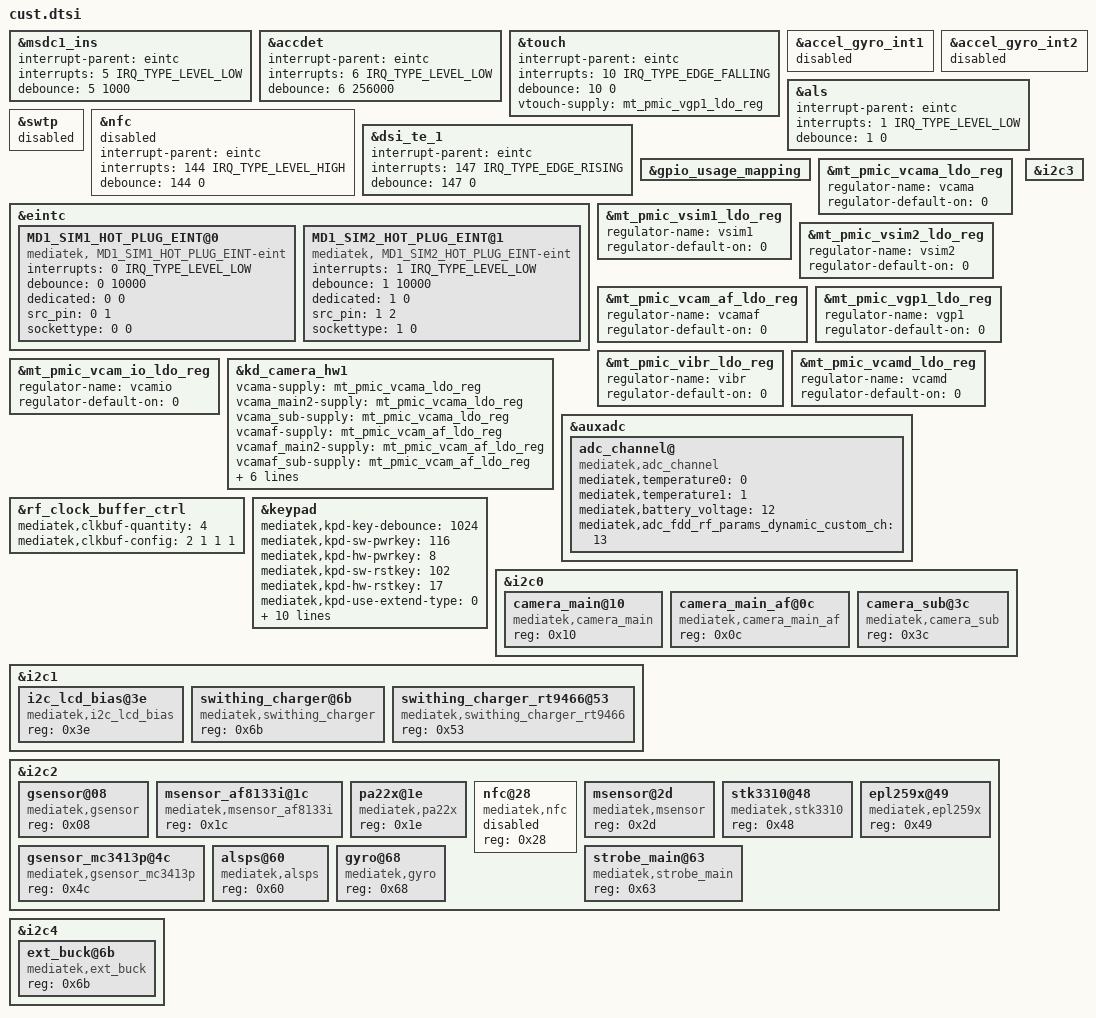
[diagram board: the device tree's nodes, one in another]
/*
 * Generated by MTK SP Drv_CodeGen Version 03.13.6  for MT6753. Copyright MediaTek Inc. (C) 2013.
 * Sun May 17 08:48:27 2026
 * Do Not Modify the File.
 */

#include <dt-bindings/interrupt-controller/irq.h>
#include <dt-bindings/interrupt-controller/arm-gic.h>

/*************************
 * EINT DTSI File
*************************/

&msdc1_ins {
	interrupt-parent = <&eintc>;
	interrupts = <5 IRQ_TYPE_LEVEL_LOW>;
	debounce = <5 1000>;
	status = "okay";
};
/* M1612 live DT dump: accdet EINT6 (m2note: EINT9). */
&accdet {
	interrupt-parent = <&eintc>;
	interrupts = <6 IRQ_TYPE_LEVEL_LOW>;
	debounce = <6 256000>;
	status = "okay";
};
&touch {
	interrupt-parent = <&eintc>;
	interrupts = <10 IRQ_TYPE_EDGE_FALLING>;
	debounce = <10 0>;
	status = "okay";
};
/* M1612 live DT dump: no accel_gyro_int nodes exist in stock (accel is
 * polled MC3XXX; EINT11/12 are cam1 rst/pnd GPIOs on this board). */
&accel_gyro_int1 {
	status = "disabled";
};
&accel_gyro_int2 {
	status = "disabled";
};
/* M1612 live DT dump: ALS/PS EINT1 (m2note: EINT18). */
&als {
	interrupt-parent = <&eintc>;
	interrupts = <1 IRQ_TYPE_LEVEL_LOW>;
	debounce = <1 0>;
	status = "okay";
};
/* M1612 live DT dump: no swtp node in stock DT. */
&swtp {
	status = "disabled";
};
&nfc {
	interrupt-parent = <&eintc>;
	interrupts = <144 IRQ_TYPE_LEVEL_HIGH>;
	debounce = <144 0>;
	status = "disabled";
};
&dsi_te_1 {
	interrupt-parent = <&eintc>;
	interrupts = <147 IRQ_TYPE_EDGE_RISING>;
	debounce = <147 0>;
	status = "okay";
};


/********************
 * GPIO USAGE MAPPING DTSI File
****************/

&gpio_usage_mapping {
};


&eintc {
	/* M1612 live DT dump: debounce 10000 (m2note 50000), sockettype 0. */
	MD1_SIM1_HOT_PLUG_EINT@0 {
		compatible = "mediatek, MD1_SIM1_HOT_PLUG_EINT-eint";
		interrupts = <0 IRQ_TYPE_LEVEL_LOW>;
		debounce = <0 10000>;
		dedicated = <0 0>;
		src_pin = <0 1>;
		sockettype = <0 0>;
	};

	MD1_SIM2_HOT_PLUG_EINT@1 {
		compatible = "mediatek, MD1_SIM2_HOT_PLUG_EINT-eint";
		interrupts = <1 IRQ_TYPE_LEVEL_LOW>;
		debounce = <1 10000>;
		dedicated = <1 0>;
		src_pin = <1 2>;
		sockettype = <1 0>;
	};
};


/*************************
 * PMIC DTSI File
*************************/

&mt_pmic_vcama_ldo_reg {
	regulator-name = "vcama";
	regulator-default-on = <0>; /* 0:skip, 1: off, 2:on */
	status = "okay";
};
&mt_pmic_vsim1_ldo_reg {
	regulator-name = "vsim1";
	regulator-default-on = <0>; /* 0:skip, 1: off, 2:on */
	status = "okay";
};
&mt_pmic_vsim2_ldo_reg {
	regulator-name = "vsim2";
	regulator-default-on = <0>; /* 0:skip, 1: off, 2:on */
	status = "okay";
};
&mt_pmic_vcam_af_ldo_reg {
	regulator-name = "vcamaf";
	regulator-default-on = <0>; /* 0:skip, 1: off, 2:on */
	status = "okay";
};
&mt_pmic_vgp1_ldo_reg {
	regulator-name = "vgp1";
	regulator-default-on = <0>; /* 0:skip, 1: off, 2:on */
	status = "okay";
};
&mt_pmic_vibr_ldo_reg {
	regulator-name = "vibr";
	regulator-default-on = <0>; /* 0:skip, 1: off, 2:on */
	status = "okay";
};
&mt_pmic_vcamd_ldo_reg {
	regulator-name = "vcamd";
	regulator-default-on = <0>; /* 0:skip, 1: off, 2:on */
	status = "okay";
};
&mt_pmic_vcam_io_ldo_reg {
	regulator-name = "vcamio";
	regulator-default-on = <0>; /* 0:skip, 1: off, 2:on */
	status = "okay";
};

&kd_camera_hw1 {
	vcama-supply = <&mt_pmic_vcama_ldo_reg>;
	vcama_main2-supply = <&mt_pmic_vcama_ldo_reg>;
	vcama_sub-supply = <&mt_pmic_vcama_ldo_reg>;

	vcamaf-supply = <&mt_pmic_vcam_af_ldo_reg>;
	vcamaf_main2-supply = <&mt_pmic_vcam_af_ldo_reg>;
	vcamaf_sub-supply = <&mt_pmic_vcam_af_ldo_reg>;

	vcamd-supply = <&mt_pmic_vcamd_ldo_reg>;
	vcamd_main2-supply = <&mt_pmic_vcamd_ldo_reg>;
	vcamd_sub-supply = <&mt_pmic_vcamd_ldo_reg>;

	vcamio-supply = <&mt_pmic_vcam_io_ldo_reg>;
	vcamio_main2-supply = <&mt_pmic_vcam_io_ldo_reg>;
	vcamio_sub-supply = <&mt_pmic_vcam_io_ldo_reg>;

	status = "okay";
};

&touch {
	vtouch-supply = <&mt_pmic_vgp1_ldo_reg>;
	status = "okay";
};


/********************************************
 *ADC DTSI File
********************************************/

&auxadc {
	adc_channel@ {
		compatible = "mediatek,adc_channel";
		mediatek,temperature0 = <0>;
		mediatek,temperature1 = <1>;
		/* M1612 live DT (soc/adc_hw@11001000/adc_channel@): battery_voltage
		 * ch 12, adc_fdd_rf_params_dynamic_custom_ch 13. */
		mediatek,battery_voltage = <12>;
		mediatek,adc_fdd_rf_params_dynamic_custom_ch = <13>;
		status = "okay";
	};
};


/**********************************************
 *CLK_BUF DTSI File
********************************************/

&rf_clock_buffer_ctrl {
	mediatek,clkbuf-quantity = <4>;
	mediatek,clkbuf-config = <2 1 1 1>;
	status = "okay";
};


/**********************************************
 *Keypad DTSI File
********************************************/

&keypad{
	mediatek,kpd-key-debounce = <1024>;
	mediatek,kpd-sw-pwrkey = <116>;
	mediatek,kpd-hw-pwrkey = <8>;
	mediatek,kpd-sw-rstkey = <102>;
	mediatek,kpd-hw-rstkey = <17>;
	mediatek,kpd-use-extend-type = <0>;
	/*HW Keycode [0~71] -> Linux Keycode*/
	mediatek,kpd-hw-map-num = <72>;
	mediatek,kpd-hw-init-map = <114 115 0 0 0 0 0 0 0 0 0 0 0 0 0 0 0 0 0 0 0 0 0 0
				0 0 0 0 0 0 0 0 0 0 0 0 0 0 0 0 0 0 0 0 0 0 0 0 
				0 0 0 0 0 0 0 0 0 0 0 0 0 0 0 0 0 0 0 0 0 0 0 0 >;
	mediatek,kpd-pwrkey-eint-gpio = <0>;
	mediatek,kpd-pwkey-gpio-din  = <0>;
	/* M1612 live DT dump: dl-key0=1 dl-key1=0 dl-key2=8. */
	mediatek,kpd-hw-dl-key0 = <1>;
	mediatek,kpd-hw-dl-key1 = <0>;
	mediatek,kpd-hw-dl-key2 = <8>;
	mediatek,kpd-hw-recovery-key = <1>;
	mediatek,kpd-hw-factory-key = <0>;
	status = "okay";
};


/*************************
 * I2C DTSI File
*************************/

/* I2C children below mirror the M1612 live DT dump verbatim
 * (bus/i2c@1100x000 nodes): camera_sub@3c (not @36), touch + LCD bias +
 * chargers on i2c1, full sensor candidate set + strobe on i2c2, i2c3 empty,
 * ext_buck on i2c4. Touch nodes get their full definition in m5s.dts. */
&i2c0 {
	#address-cells = <1>;
	#size-cells = <0>;
	camera_main@10 {
		compatible = "mediatek,camera_main";
		reg = <0x10>;
		status = "okay";
	};
	camera_main_af@0c {
		compatible = "mediatek,camera_main_af";
		reg = <0x0c>;
		status = "okay";
	};
	camera_sub@3c {
		compatible = "mediatek,camera_sub";
		reg = <0x3c>;
		status = "okay";
	};
};

&i2c1 {
	#address-cells = <1>;
	#size-cells = <0>;
	i2c_lcd_bias@3e {
		compatible = "mediatek,i2c_lcd_bias";
		reg = <0x3e>;
		status = "okay";
	};
	swithing_charger@6b {
		compatible = "mediatek,swithing_charger";
		reg = <0x6b>;
		status = "okay";
	};
	swithing_charger_rt9466@53 {
		compatible = "mediatek,swithing_charger_rt9466";
		reg = <0x53>;
		status = "okay";
	};
};

&i2c2 {
	#address-cells = <1>;
	#size-cells = <0>;
	gsensor@08 {
		compatible = "mediatek,gsensor";
		reg = <0x08>;
		status = "okay";
	};
	msensor_af8133i@1c {
		compatible = "mediatek,msensor_af8133i";
		reg = <0x1c>;
		status = "okay";
	};
	pa22x@1e {
		compatible = "mediatek,pa22x";
		reg = <0x1e>;
		status = "okay";
	};
	nfc@28 {
		compatible = "mediatek,nfc";
		reg = <0x28>;
		status = "disabled";
	};
	msensor@2d {
		compatible = "mediatek,msensor";
		reg = <0x2d>;
		status = "okay";
	};
	stk3310@48 {
		compatible = "mediatek,stk3310";
		reg = <0x48>;
		status = "okay";
	};
	epl259x@49 {
		compatible = "mediatek,epl259x";
		reg = <0x49>;
		status = "okay";
	};
	gsensor_mc3413p@4c {
		compatible = "mediatek,gsensor_mc3413p";
		reg = <0x4c>;
		status = "okay";
	};
	alsps@60 {
		compatible = "mediatek,alsps";
		reg = <0x60>;
		status = "okay";
	};
	strobe_main@63 {
		compatible = "mediatek,strobe_main";
		reg = <0x63>;
		status = "okay";
	};
	gyro@68 {
		compatible = "mediatek,gyro";
		reg = <0x68>;
		status = "okay";
	};
};

&i2c3 {
	#address-cells = <1>;
	#size-cells = <0>;
};

&i2c4 {
	#address-cells = <1>;
	#size-cells = <0>;
	ext_buck@6b {
		compatible = "mediatek,ext_buck";
		reg = <0x6b>;
		status = "okay";
	};
};
